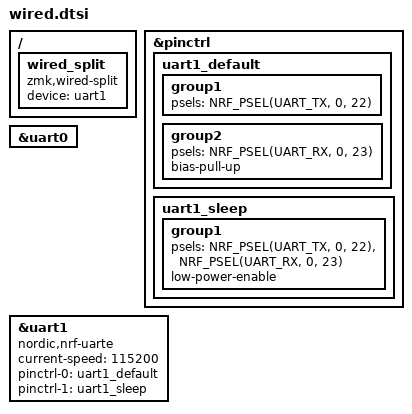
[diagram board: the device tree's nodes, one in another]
&pinctrl {
	uart1_default: uart1_default {
		group1 {
			psels = <NRF_PSEL(UART_TX, 0, 22)>;
		};
		group2 {
			psels = <NRF_PSEL(UART_RX, 0, 23)>;
			bias-pull-up;
		};
	};

	uart1_sleep: uart1_sleep {
		group1 {
			psels = <NRF_PSEL(UART_TX, 0, 22)>,
					<NRF_PSEL(UART_RX, 0, 23)>;
			low-power-enable;
		};
	};
};

&uart0 {
	status = "okay";
};

&uart1 {
	compatible = "nordic,nrf-uarte";
	status = "okay";
	current-speed = <115200>;
	pinctrl-0 = <&uart1_default>;
	pinctrl-1 = <&uart1_sleep>;
	pinctrl-names = "default", "sleep";
};

/ {
	wired_split: wired_split {
		compatible = "zmk,wired-split";
		device = <&uart1>;
	};
};
